# BlueNRG_LP register map
File version: 1.0
CPU: CM0+ r0p0, little endian, no MPU, no FPU, 2 interrupt priority bits
Registers are 32-bit, read-write, reset 0x0 unless marked. A register's access mark holds for its fields unless they carry their own. Offsets are from the block's base; lines under a group give offsets from that group; [hi:lo] are bit positions; {n}, {i} and the like mark numbered series; 'fields as' and 'values as' point back to an identical list; <NAME> marks a mode.

## Memory map
0x40000000 SYSCFG size 0x3F — System configuration controller
0x40001000 FLASH size 0x90
0x40002000 TIM1 size 0x400 — Advanced-timers
0x40003000 IWDG size 0x400 — Independent watchdog
0x40004000 RTC size 0x400 — Real-time clock
0x41000000 I2C1 size 0x400 — Inter-integrated circuit
0x41001000 I2C2 size 0x400
0x41002000 SPI1 size 0x400 — Serial peripheral interface/Inter-IC sound
0x41003000 SPI2 size 0x400
0x41004000 USART1 size 0x3FF — Universal synchronous asynchronous receiver transmitter
0x41005000 LPUART1 size 0x400 — Universal synchronous asynchronous receiver transmitter
0x41006000 ADC size 0x400
0x41007000 SPI3 size 0x400
0x48000000 GPIOA size 0x400 — General-purpose I/Os
0x48100000 GPIOB size 0x400 — General-purpose I/Os
0x48200000 CRC size 0x400 — Cyclic redundancy check calculation unit
0x48300000 PKA size 0x1000
0x48400000 RCC size 0xFFFF — Reset and clock control
0x48500000 PWR size 0x400 — Power control
0x48600000 RNG size 0x400 — Random number generator
0x48700000 DMA size 0x400 — Direct memory access controller
0x48800000 DMAMUX size 0x400 — Direct memory access Multiplexer
0x60000000 BLUE size 0x1000
0x60001000 RADIO_CTRL size 0x400 — Radio Controller
0x60001400 RRM size 0x400 — Wakeup block version register
0x60001800 WAKEUP size 0x1000

## Interrupts
0 FLASH — NVM interrupt
1 RCC — RCC interrupt
2 PVD_BORH (BLUE) — PVD/BORH interrupt
3 I2C1 — I2C1 interrurpt
4 I2C2 — I2C2 interrupt
5 SPI1 — SPI1 interrupt
6 SPI2 — SPI2 interrupt
7 SPI3 — SPI3 interrupt
8 USART1 — USART interrupt
9 LPUART (LPUART1) — Low Power UART interrupt
10 TIM1 — Timer 1 interrupt
11 RTC — RTC interrupt
12 ADC — ADC interrupt
13 PKA — PKA interrupt
15 GPIOA — GPIOA interrupt
16 GPIOB — GPIOB interrupt
17 DMA — DMA interrupt
18 BLE_TX_RX_IRQn (BLUE) — BLE Tx/Rx interrupt
19 BLE_AES_IRQn (BLUE) — BLE AES interrupt
20 BLE_DBG_IRQn (BLUE) — BLE Debug interrupt
21 RADIO_CTRL_IRQn (RADIO_CTRL) — Radio Control interrupt
22 MR_BLE_IRQn (BLUE) — RRM and Radio FSM interrupt
23 CPU_WKUP_IRQn (BLUE) — CPU Wakeup interrupt
24 BLE_WKUP_IRQn (BLUE) — BLE Wakeup interrupt

## BLUE
Base 0x60000000
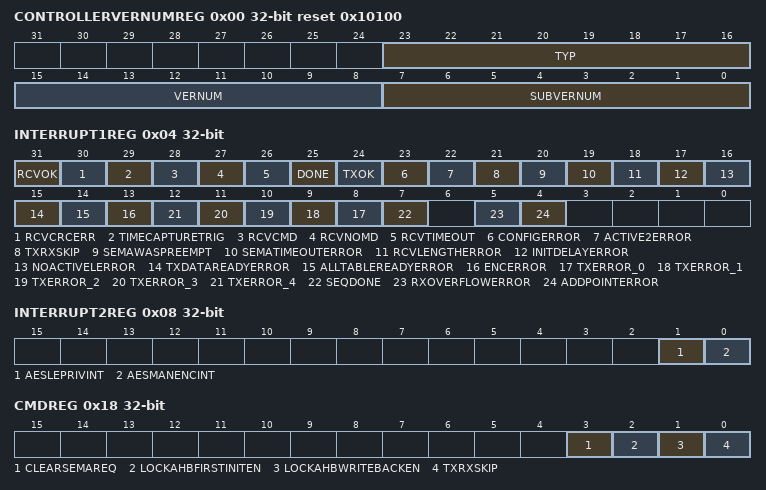
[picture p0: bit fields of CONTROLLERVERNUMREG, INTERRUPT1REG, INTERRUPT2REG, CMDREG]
0x00 CONTROLLERVERNUMREG ro reset 0x10100 — Controller Version Number register
  [23:16] TYP, [15:8] VERNUM, [7:0] SUBVERNUM
0x04 INTERRUPT1REG — Interrupt1 register
  [31] RCVOK, [30] RCVCRCERR, [29] TIMECAPTURETRIG, [28] RCVCMD, [27] RCVNOMD, [26] RCVTIMEOUT, [25] DONE, [24] TXOK, [23] CONFIGERROR, [22] ACTIVE2ERROR, [21] TXRXSKIP, [20] SEMAWASPREEMPT, [19] SEMATIMEOUTERROR, [18] RCVLENGTHERROR, [17] INITDELAYERROR, [16] NOACTIVELERROR, [15] TXDATAREADYERROR, [14] ALLTABLEREADYERROR, [13] ENCERROR, [n+8] TXERROR_{n} (n=0..4), [7] SEQDONE, [5] RXOVERFLOWERROR, [4] ADDPOINTERROR
0x08 INTERRUPT2REG — Interrupt2 register
  [1] AESLEPRIVINT, [0] AESMANENCINT
0x0C TIMEOUTDESTREG — TimeoutDest register
  [1:0] DESTINATION
0x10 TIMEOUTREG — Timeout register
  [31:0] TIMEOUT
0x14 TIMERCAPTUREREG ro — TimerCapture register
  [31:0] TIMERCAPTURE
0x18 CMDREG — Cmd register
  [3] CLEARSEMAREQ, [2] LOCKAHBFIRSTINITEN, [1] LOCKAHBWRITEBACKEN, [0] TXRXSKIP
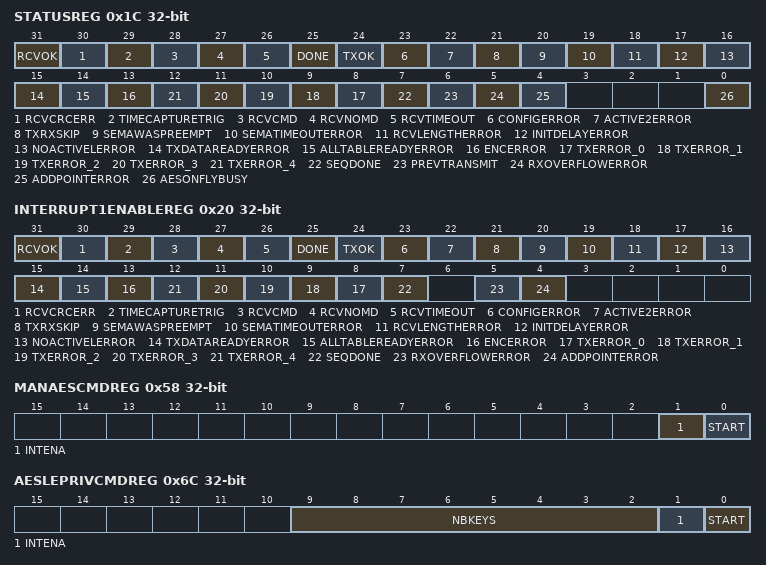
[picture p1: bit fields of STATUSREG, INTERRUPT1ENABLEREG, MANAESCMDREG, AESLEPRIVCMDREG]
0x1C STATUSREG ro — Status register
  [31] RCVOK, [30] RCVCRCERR, [29] TIMECAPTURETRIG, [28] RCVCMD, [27] RCVNOMD, [26] RCVTIMEOUT, [25] DONE, [24] TXOK, [23] CONFIGERROR, [22] ACTIVE2ERROR, [21] TXRXSKIP, [20] SEMAWASPREEMPT, [19] SEMATIMEOUTERROR, [18] RCVLENGTHERROR, [17] INITDELAYERROR, [16] NOACTIVELERROR, [15] TXDATAREADYERROR, [14] ALLTABLEREADYERROR, [13] ENCERROR, [n+8] TXERROR_{n} (n=0..4), [7] SEQDONE, [6] PREVTRANSMIT, [5] RXOVERFLOWERROR, [4] ADDPOINTERROR, [0] AESONFLYBUSY
0x20 INTERRUPT1ENABLEREG ro — Interrupt1Enable register
  fields as INTERRUPT1REG
0x24 INTERRUPT1LATENCYREG ro — Interrupt1Latency register
  [7:0] INTERRUPT1LATENCY
{0x28+4i} MANAESKEY{i}REG (i=0..3) — ManAesKey{i} register
  [31:0] MANAESKEY_{32i+31}_{32i}
{0x38+4i} MANAESCLEARTEXT{i}REG (i=0..3) — ManAesClearText{i} register
  [31:0] AES_CLEAR_{32i+31}_{32i}
{0x48+4i} MANAESCIPHERTEXT{i}REG ro (i=0..3) — ManAESCipherText{i} register
  [31:0] AES_CIPHER_{32i+31}_{32i}
0x58 MANAESCMDREG — ManAESCmd register
  [1] INTENA, [0] START
0x5C MANAESSTATREG ro — ManAESStat register
  [0] BUSY
0x60 AESLEPRIVPOINTERREG — AesLePrivPointer register
  [23:0] POINTER
0x64 AESLEPRIVHASHREG — AesLePrivHash register
  [23:0] HASH
0x68 AESLEPRIVPRANDREG — AesLePrivPrand register
  [23:0] PRAND
0x6C AESLEPRIVCMDREG — AesLePrivCmd register
  [9:2] NBKEYS, [1] INTENA, [0] START
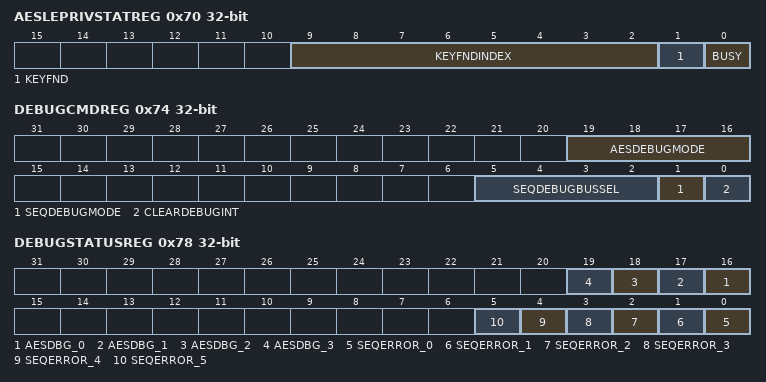
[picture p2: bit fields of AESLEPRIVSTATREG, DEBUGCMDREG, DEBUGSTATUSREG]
0x70 AESLEPRIVSTATREG ro — AesLePrivStat register
  [9:2] KEYFNDINDEX, [1] KEYFND, [0] BUSY
0x74 DEBUGCMDREG — DebugCmd register
  [19:16] AESDEBUGMODE, [5:2] SEQDEBUGBUSSEL, [1] SEQDEBUGMODE, [0] CLEARDEBUGINT
0x78 DEBUGSTATUSREG ro — DebugStatus register
  [n+16] AESDBG_{n} (n=0..3), [n] SEQERROR_{n} (n=0..5)
0x7C SPARE — SpareReg register
